# EFR32BG24A610F1536IM40 register map
Vendor: Silicon Labs; Series: EFR32; File version: B
Registers are 32-bit, read-write, reset 0x0 unless marked. A register's access mark holds for its fields unless they carry their own. Offsets are from the block's base; [hi:lo] are bit positions.

## SCRATCHPAD_S — SCRATCHPAD_S Registers
Base 0x40000000
Same registers: SCRATCHPAD_NS 0x50000000, RFSCRATCHPAD_S 0xA8024000, RFSCRATCHPAD_NS 0xB8024000
0x00 SREG0 — Used for SIMCTRL Pointer in Verification Environment
  [31:0] SCRATCH — Scratch Pad Register
0x04 SREG1 — Used for SIMCTRL Data Access in Verification Environment
  [31:0] SCRATCH

## HFRCO0_S — HFRCO0_S Registers
Base 0x40010000
Same registers: HFRCOEM23_S 0x4A000000, HFRCO0_NS 0x50010000, HFRCOEM23_NS 0x5A000000
0x00 IPVERSION ro reset 0x2
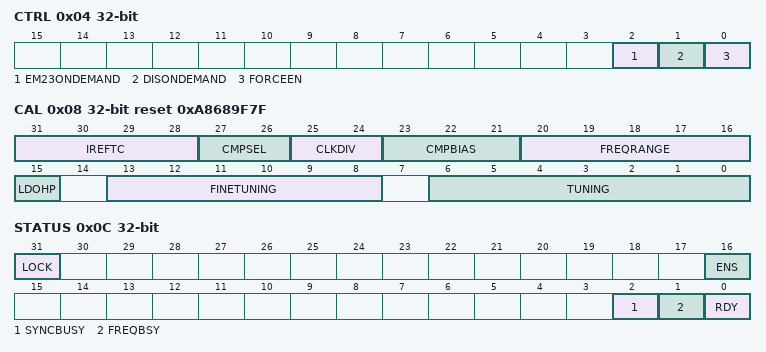
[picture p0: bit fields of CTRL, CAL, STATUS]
0x04 CTRL
  [2] EM23ONDEMAND
  [1] DISONDEMAND — Disable On-demand
  [0] FORCEEN — Force Enable
0x08 CAL reset 0xA8689F7F
  [31:28] IREFTC — Tempco Trim on Comparator Current
  [27:26] CMPSEL — Comparator Load Select
  [25:24] CLKDIV — Locally Divide HFRCO Clock Output
    0=DIV1 (Divide by 1.); 1=DIV2 (Divide by 2.); 2=DIV4 (Divide by 4.)
  [23:21] CMPBIAS — Comparator Bias Current
  [20:16] FREQRANGE — Frequency Range
  [15] LDOHP — LDO High Power Mode
  [13:8] FINETUNING — Fine Tuning Value
  [6:0] TUNING — Tuning Value
0x0C STATUS ro
  [31] LOCK — Lock Status
    0=UNLOCKED (HFRCO is unlocked); 1=LOCKED (HFRCO is locked)
  [16] ENS — Enable Status
  [2] SYNCBUSY — Synchronization Busy
  [1] FREQBSY — Frequency Updating Busy
  [0] RDY — Ready
0x10 IF
  [0] RDY — Ready Interrupt Flag
0x14 IEN
  [0] RDY — RDY Interrupt Enable
0x1C LOCK wo reset 0x8195
  [15:0] LOCKKEY
    0x8195=UNLOCK (Unlock code)

## FSRCO_S — FSRCO_S Registers
Base 0x40018000
Same registers: FSRCO_NS 0x50018000
0x00 IPVERSION ro

## DPLL0_S — DPLL0_S Registers
Base 0x4001C000
Same registers: DPLL0_NS 0x5001C000
0x00 IPVERSION ro reset 0x1
  [31:0] IPVERSION — IP Version ID
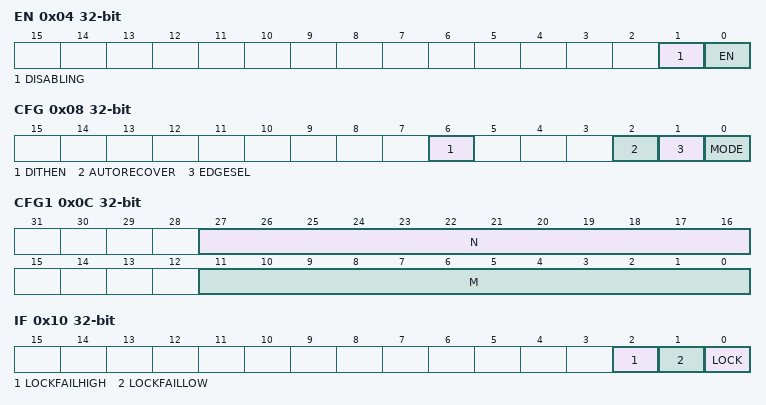
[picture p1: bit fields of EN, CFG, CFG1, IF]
0x04 EN
  [1] DISABLING ro — Disablement Busy Status
  [0] EN — Module Enable
0x08 CFG
  [6] DITHEN — Dither Enable Control
  [2] AUTORECOVER — Automatic Recovery Control
  [1] EDGESEL — Reference Edge Select
  [0] MODE — Operating Mode Control
    0=FLL (Frequency Lock Mode); 1=PLL (Phase Lock Mode)
0x0C CFG1
  [27:16] N — Factor N
  [11:0] M — Factor M
0x10 IF
  [2] LOCKFAILHIGH — Lock Failure High Interrupt Flag
  [1] LOCKFAILLOW — Lock Failure Low Interrupt Flag
  [0] LOCK — Lock Interrupt Flag
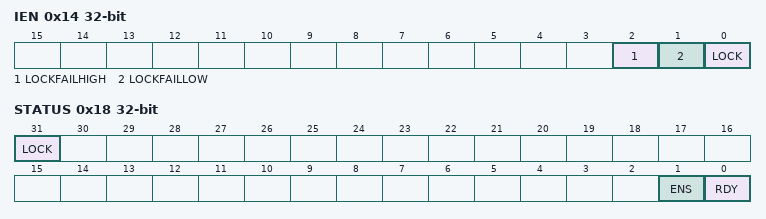
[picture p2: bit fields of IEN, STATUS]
0x14 IEN
  [2] LOCKFAILHIGH — LOCKFAILHIGH Interrupt Enable
  [1] LOCKFAILLOW — LOCKFAILLOW Interrupe Enable
  [0] LOCK — LOCK interrupt Enable
0x18 STATUS ro
  [31] LOCK — Lock Status
    0=UNLOCKED (DPLL is unlocked); 1=LOCKED (DPLL is locked)
  [1] ENS — Enable Status
  [0] RDY — Ready Status
0x24 LOCK wo reset 0x7102
  [15:0] LOCKKEY
    0x7102=UNLOCK (Unlock code)

## LFXO_S — LFXO_S Registers
Base 0x40020000
Same registers: LFXO_NS 0x50020000
0x00 IPVERSION ro reset 0x1
  [31:0] IPVERSION — IP Version ID
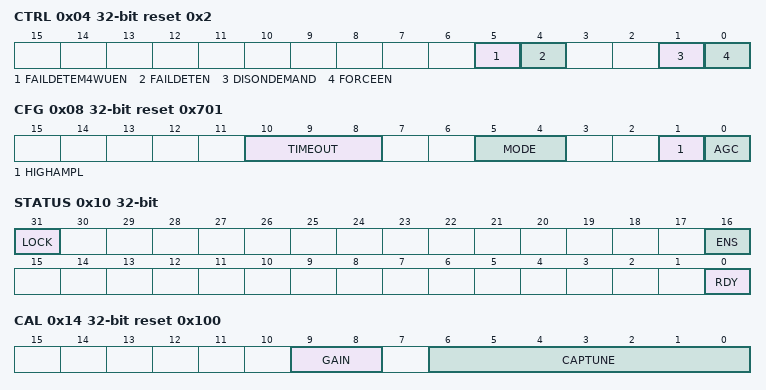
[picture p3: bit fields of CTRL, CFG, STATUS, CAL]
0x04 CTRL reset 0x2
  [5] FAILDETEM4WUEN — LFXO Failure Detection EM4WU Enable
  [4] FAILDETEN — LFXO Failure Detection Enable
  [1] DISONDEMAND — LFXO Disable On-demand requests
  [0] FORCEEN — LFXO Force Enable
0x08 CFG reset 0x701 — Do not write to this register unless the oscillator is forced off. The oscillator is forced off if DISONDEMAND is set and FORCEEN is cleared.
  [10:8] TIMEOUT — LFXO Start-up Delay
    0=CYCLES2 (Timeout period of 2 cycles); 1=CYCLES256 (Timeout period of 256 cycles); 2=CYCLES1K (Timeout period of 1024 cycles); 3=CYCLES2K (Timeout period of 2048 cycles); 4=CYCLES4K (Timeout period of 4096 cycles); 5=CYCLES8K (Timeout period of 8192 cycles); 6=CYCLES16K (Timeout period of 16384 cycles); 7=CYCLES32K (Timeout period of 32768 cycles)
  [5:4] MODE — LFXO Mode
    0=XTAL (A 32768Hz crystal should be connected to the LF crystal pads. Voltage must not exceed VDDIO.); 1=BUFEXTCLK (An external sine source with minimum amplitude 100mv (zero-to-peak) and maximum amplitude 500mV (zero-to-peak) should be connected in series with LFXTAL_I pin. Minimum voltage should be larger than ground and maximum voltage smaller than VDDIO. The sine source does not need to be ac coupled externally as it is ac couples inside LFXO. LFXTAL_O is free to be used as a general purpose GPIO.); 2=DIGEXTCLK (An external 32KHz CMOS clock should be provided on LFXTAL_I. LFXTAL_O is free to be used as a general purpose GPIO.)
  [1] HIGHAMPL — LFXO High Amplitude Enable
  [0] AGC — LFXO AGC Enable
0x10 STATUS ro
  [31] LOCK — LFXO Locked Status
    0=UNLOCKED (LFXO lockable registers are not locked); 1=LOCKED (LFXO lockable registers are locked)
  [16] ENS — LFXO Enable Status
  [0] RDY — LFXO Ready Status
0x14 CAL reset 0x100 — Do not write to this register unless CALBSY in SYNCBUSY register is low.
  [9:8] GAIN — LFXO Startup Gain
  [6:0] CAPTUNE — Internal Capacitance Tuning
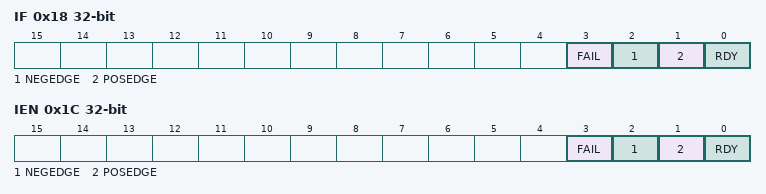
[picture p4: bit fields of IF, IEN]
0x18 IF
  [3] FAIL — LFXO Failure Interrupt Flag
  [2] NEGEDGE — Falling Edge Interrupt Flag
  [1] POSEDGE — Rising Edge Interrupt Flag
  [0] RDY — LFXO Ready Interrupt Flag
0x1C IEN
  [3] FAIL — LFXO Failure Interrupt Enable
  [2] NEGEDGE — Falling Edge Interrupt Enable
  [1] POSEDGE — Rising Edge Interrupt Enable
  [0] RDY — LFXO Ready Interrupt Enable
0x20 SYNCBUSY ro
  [0] CAL — LFXO Synchronization status
0x24 LOCK wo reset 0x1A20
  [15:0] LOCKKEY
    0x1A20=UNLOCK (Unlock LFXO lockable registers)
